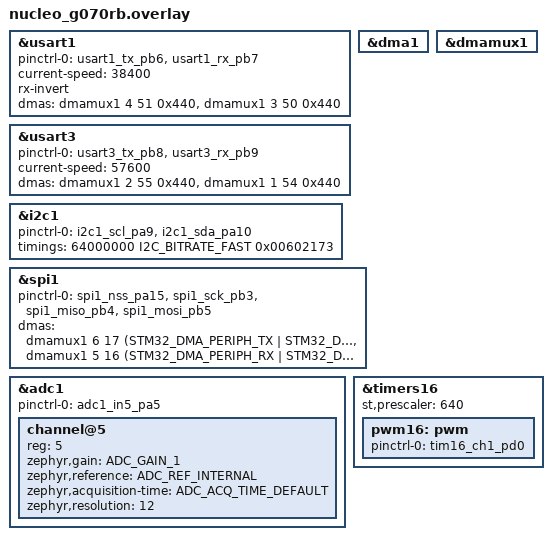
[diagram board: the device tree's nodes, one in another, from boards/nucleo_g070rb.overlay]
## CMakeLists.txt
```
# SPDX-License-Identifier: Apache-2.0

cmake_minimum_required(VERSION 3.20.0)
find_package(Zephyr REQUIRED HINTS $ENV{ZEPHYR_BASE})
project(lapan_imubk)

target_sources(app PRIVATE
	src/main.cpp
	src/sen_mti3.cpp
	src/sen_adxl.cpp
	src/sen_lsm6.cpp
	src/sen_lis3.cpp
	src/sen_ms56.cpp
	src/com_uart.cpp
	src/protocol_mgr.cpp
	src/util.cpp
	src/minmea.c
	)
```

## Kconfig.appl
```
mainmenu "MTIG4"

source "Kconfig.zephyr"
config MYAPP_STM32
	default y
	bool
	select USE_STM32_HAL_I2C
```

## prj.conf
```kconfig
CONFIG_CPP=y
CONFIG_NEWLIB_LIBC=y

CONFIG_I2C=y
CONFIG_PWM=y
CONFIG_ADC=y
CONFIG_ADC_STM32=y
# CONFIG_I2C_CALLBACK=y
# CONFIG_UART=y
CONFIG_UART_ASYNC_API=y

CONFIG_SPI=y
CONFIG_RING_BUFFER=y
CONFIG_SPI_STM32_DMA=y
# CONFIG_SPI_STM32_INTERRUPT=y
CONFIG_SPI_ASYNC=y
CONFIG_LOG=y
CONFIG_LOG_BACKEND_RTT=y
# CONFIG_SHELL=y
# CONFIG_SHELL_BACKENDS=y
# CONFIG_SHELL_BACKEND_RTT=y    

CONFIG_SPEED_OPTIMIZATIONS=y


CONFIG_BOOT_BANNER=n
# CONFIG_STDOUT_CONSOLE=y
# CONFIG_UART_CONSOLE=n
# CONFIG_RTT_CONSOLE=y
# CONFIG_USE_SEGGER_RTT=y
# CONFIG_THREAD_NAME=y
# CONFIG_DEBUG=y
# CONFIG_THREAD_ANALYZER=y
# CONFIG_THREAD_ANALYZER_AUTO=y
# CONFIG_THREAD_ANALYZER_AUTO_INTERVAL=10
# CONFIG_THREAD_ANALYZER_USE_LOG=y
```

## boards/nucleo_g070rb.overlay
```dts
&usart1 {
	pinctrl-0 = <&usart1_tx_pb6 &usart1_rx_pb7>;
	pinctrl-names = "default";
	current-speed = <38400>;
	status = "okay";
	rx-invert;

	dmas = <&dmamux1 4 51 0x440>,
	       <&dmamux1 3 50 0x440>;
	dma-names = "tx", "rx";
};

// &usart2 {
// 	pinctrl-0 = <&usart2_tx_pa2 &usart2_rx_pa3>;
// 	pinctrl-names = "default";
// 	current-speed = <115200>;
// 	status = "okay";
// };

&usart3 {
	pinctrl-0 = <&usart3_tx_pb8 &usart3_rx_pb9>;
	pinctrl-names = "default";
	current-speed = <57600>;
	status = "okay";
	
	dmas = <&dmamux1 2 55 0x440>,
	       <&dmamux1 1 54 0x440>;
	dma-names = "tx", "rx";
};


// &usart4 {
// 	pinctrl-0 = <&usart4_tx_pa0 &usart4_rx_pa1>;
// 	pinctrl-names = "default";
// 	current-speed = <115200>;
// 	status = "okay";
// };

&dma1 {
	status = "okay";
};

&dmamux1 {	
	status = "okay";
};

&i2c1 {
	pinctrl-0 = <&i2c1_scl_pa9 &i2c1_sda_pa10>;
    timings = <64000000 I2C_BITRATE_FAST 0x00602173>;
};

&spi1 {
	pinctrl-0 = <&spi1_nss_pa15 &spi1_sck_pb3 &spi1_miso_pb4 &spi1_mosi_pb5>;
	status = "okay";
	dmas = <&dmamux1 6 17 (STM32_DMA_PERIPH_TX | STM32_DMA_PRIORITY_HIGH)>,
		   <&dmamux1 5 16 (STM32_DMA_PERIPH_RX | STM32_DMA_PRIORITY_HIGH)>;
	dma-names = "tx", "rx";
};

&adc1 {
	#address-cells = <1>;
	#size-cells = <0>;

	pinctrl-0 = <&adc1_in5_pa5 >;
	pinctrl-names = "default";
	status = "okay";

	channel@5 {
		reg = <5>;
		zephyr,gain = "ADC_GAIN_1";
		zephyr,reference = "ADC_REF_INTERNAL";
		zephyr,acquisition-time = <ADC_ACQ_TIME_DEFAULT>;
		zephyr,resolution = <12>;
	};
};

&timers16 {
	st,prescaler = <640>;
	status = "okay";

	pwm16: pwm {
		status = "okay";
		pinctrl-0 = <&tim16_ch1_pd0>;
		pinctrl-names = "default";
	};
};
```

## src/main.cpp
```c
#include <stdint.h>
#include <stdio.h>
#include <stdlib.h>
#include <string.h>
#include <zephyr/kernel.h>
#include <zephyr/device.h>
#include <zephyr/drivers/gpio.h>
#include <zephyr/drivers/uart.h>
#include <zephyr/drivers/pwm.h>
#include <zephyr/drivers/adc.h>
#include <zephyr/sys/ring_buffer.h>

#include "sen_mti3.hpp"
#include "sen_adxl.hpp"
#include "sen_lsm6.hpp"
#include "sen_lis3.hpp"
#include "sen_ms56.hpp"
#include "com_uart.hpp"
#include "protocol_mgr.hpp"
#include "util.hpp"
#include "data.hpp"
#include "minmea.h"

#define STACKSIZE 1024
#define SMALLSTACKSIZE	512

#define ADXL_ADDR 0x53
#define LSM6_ADDR 0x6A
#define LIS3_ADDR 0x1E
#define MS56_ADDR 0x77

#ifndef ARCH_STACK_PTR_ALIGN
#define ARCH_STACK_PTR_ALIGN 8
#endif

static const struct device *const gpib		= DEVICE_DT_GET(DT_NODELABEL(gpiob));
static const struct device *const gpic		= DEVICE_DT_GET(DT_NODELABEL(gpioc));
static const struct device *const gpid		= DEVICE_DT_GET(DT_NODELABEL(gpiod));
static const struct device *const adcc1		= DEVICE_DT_GET(DT_NODELABEL(adc1));
static const struct device *const pwm_bz	= DEVICE_DT_GET(DT_NODELABEL(pwm16));
static const struct device *const spi_sen	= DEVICE_DT_GET(DT_NODELABEL(spi1));
static const struct device *const i2c_sen	= DEVICE_DT_GET(DT_NODELABEL(i2c2));
static const struct device *const uart_com	= DEVICE_DT_GET(DT_NODELABEL(usart3));
static const struct device *const uart_gps	= DEVICE_DT_GET(DT_NODELABEL(usart1));

static struct adc_channel_cfg adc1c5c = ADC_CHANNEL_CFG_DT(DT_CHILD(DT_NODELABEL(adc1), channel_5));

// Sensors are ring-buffered, except GPS and MS5611 since they works in round robin
RING_BUF_DECLARE(adxl_ring_buf, sizeof(ADXLRawData) * 2);
RING_BUF_DECLARE(lsm6_ring_buf, sizeof(LSM6RawData) * 2);
RING_BUF_DECLARE(lis3_ring_buf, sizeof(LIS3RawData) * 2);
RING_BUF_DECLARE(mti3_ring_buf, sizeof(MTI3RawData) * 2);
MS56RawData ms56_buf;
NMEARawData nmea_buf;

struct spi_config spi_sen_cfg = {
	.frequency = 1000000U,
	.operation = SPI_OP_MODE_MASTER | SPI_MODE_CPOL | SPI_MODE_CPHA | SPI_WORD_SET(8) | SPI_TRANSFER_MSB,
};

uint32_t i2c_sen_cfg = I2C_SPEED_SET(I2C_SPEED_FAST) | I2C_MODE_CONTROLLER;

uint16_t adcbuf;
struct adc_sequence adc_sen_seq = {
	.channels = 0b0000000000100000,
	.buffer = &adcbuf,
	.buffer_size = sizeof(adcbuf),
	.resolution = 12,
};

MTI3 *mti3 = new MTI3(spi_sen, spi_sen_cfg);
ADXL *adxl = new ADXL(i2c_sen, ADXL_ADDR);
LSM6 *lsm6 = new LSM6(i2c_sen, LSM6_ADDR);
LIS3 *lis3 = new LIS3(i2c_sen, LIS3_ADDR);
MS56 *ms56 = new MS56(i2c_sen, MS56_ADDR);

DATCOM *datcom = new DATCOM(uart_com);

// Should use semaphore instead of flags, but whatever
uint8_t sen_i2c_flag = 0;
uint8_t sen_spi_flag = 0;
uint8_t com_send_imu_flag = 0;
uint8_t com_send_gps_flag = 0;
uint8_t ctx_finish_flag = 0;
uint8_t buz_ping_flag = 0;
uint8_t uart_com_flag = 0;
uint8_t uart_gps_flag = 0;

uint8_t pktcounter = 0;
uint8_t rate_buz = 1;
uint8_t uart_com_buf[32];
uint8_t uart_gps_buf[128];

uart_event_rx com_uart_evt;
uart_event_rx gps_uart_evt;

///////////////////////////////////////////////////////////////////////////////
//	PREDECLARATIONS
///////////////////////////////////////////////////////////////////////////////

void sen_poll_exp(struct k_timer *timer);
void gps_poll_exp(struct k_timer *timer);
void dat_ping_exp(struct k_timer *timer);

K_TIMER_DEFINE(timer_sen, sen_poll_exp, NULL);
K_TIMER_DEFINE(timer_gps, gps_poll_exp, NULL);
K_TIMER_DEFINE(timer_buz, dat_ping_exp, NULL);

void buzzer_ping(int16_t freq)
{
	int8_t ret = 0;
	if (freq > 0)
	{
		ret = pwm_set_cycles(pwm_bz, 1, 100000 / freq, 50000 / freq, PWM_POLARITY_NORMAL);
	}
	else
	{
		ret = pwm_set_cycles(pwm_bz, 1, 10, 0, PWM_POLARITY_NORMAL);
	}
}

///////////////////////////////////////////////////////////////////////////////
//	SERIAL INTERRUPT CALLBACK
///////////////////////////////////////////////////////////////////////////////

void com_uart_cb(const struct device *dev, struct uart_event *evt, void *user_data)
{
	switch (evt->type)
	{
	case UART_TX_DONE:
		ctx_finish_flag = 1;
		break;
	case UART_TX_ABORTED:
		// should do something here really...
		break;
	case UART_RX_RDY:
		com_uart_evt = evt->data.rx;
		uart_com_flag = 1;
		break;
	default:
		break;
	}
}

void gps_uart_cb(const struct device *dev, struct uart_event *evt, void *user_data)
{
	switch (evt->type)
	{
	case UART_RX_RDY:
		gps_uart_evt = evt->data.rx;
		uart_gps_flag = 1;
		break;
	default:
		break;
	}
}

///////////////////////////////////////////////////////////////////////////////
//	DATA ACQUISITION
///////////////////////////////////////////////////////////////////////////////

void adxl_get_data()
{
	uint8_t cnt = 2;
	uint8_t adxldata[sizeof(ADXLRawData) * cnt];
	adxl->getMeasurement(adxldata, &cnt);
	for (int8_t i = 0; i < cnt; i++)
	{
		ring_buf_put(&adxl_ring_buf, &adxldata[i * sizeof(ADXLRawData)], sizeof(ADXLRawData));
	}
}

void lsm6_get_data()
{
	uint8_t cnt = 1;
	uint8_t lsm6data[sizeof(LSM6RawData)];
	lsm6->getMeasurement(lsm6data, &cnt);
	for (int8_t i = 0; i < cnt; i++)
	{
		ring_buf_put(&lsm6_ring_buf, &lsm6data[i * sizeof(LSM6RawData)], sizeof(LSM6RawData));
	}
}

void lis3_get_data()
{
	uint8_t cnt = 2;
	uint8_t lis3data[6];
	lis3->getMeasurement(lis3data, &cnt);

	for (int8_t i = 0; i < cnt; i++)
	{
		ring_buf_put(&lis3_ring_buf, &lis3data[i * sizeof(LIS3RawData)], sizeof(LIS3RawData));
	}
}

void ms56_get_data()
{
	uint8_t cnt = 1;
	ms56->getMeasurement((uint8_t *)&ms56_buf, &cnt);
}

uint32_t mti3_parse_32b(uint8_t *data)
{
	return data[0] << 24 | data[1] << 16 | data[2] << 8 | data[3];
}

int8_t mti3_parse_measdata(uint8_t *measData, uint8_t len, MTI3RawData *data)
{
	if (len < 2)
	{
		return -1;
	}

	if (measData[0] != XSENS_MTDATA2)
	{
		return -2;
	}

	if (len - 3 != measData[1])
	{
		return -3;
	}

	uint8_t idx = 2;

	while (idx < (len - 3))
	{
		uint16_t dataID = ((uint16_t)measData[idx + 1] | ((uint16_t)measData[idx] << 8));
		uint8_t dataLen = measData[idx + 2];

		switch (dataID & 0xFFFF0)
		{
		case XDI_ACCELERATION:
			data->accX = mti3_parse_32b(&measData[idx + 3]);
			data->accY = mti3_parse_32b(&measData[idx + 7]);
			data->accZ = mti3_parse_32b(&measData[idx + 11]);
			break;
		case XDI_RATEOFTURN:
			data->rotX = mti3_parse_32b(&measData[idx + 3]);
			data->rotY = mti3_parse_32b(&measData[idx + 7]);
			data->rotZ = mti3_parse_32b(&measData[idx + 11]);
			break;
		case XDI_MAGNETICFIELD:
			data->magX = mti3_parse_32b(&measData[idx + 3]);
			data->magY = mti3_parse_32b(&measData[idx + 7]);
			data->magZ = mti3_parse_32b(&measData[idx + 11]);
			break;
		case XDI_EULERANGLES:
			data->roll = mti3_parse_32b(&measData[idx + 3]);
			data->pitch = mti3_parse_32b(&measData[idx + 7]);
			data->yaw = mti3_parse_32b(&measData[idx + 11]);
			break;
		case XDI_DELTAV:
			data->dvX = mti3_parse_32b(&measData[idx + 3]);
			data->dvY = mti3_parse_32b(&measData[idx + 7]);
			data->dvZ = mti3_parse_32b(&measData[idx + 11]);
			break;
		case XDI_DELTAQ:
			data->dqA = mti3_parse_32b(&measData[idx + 3]);
			data->dqB = mti3_parse_32b(&measData[idx + 7]);
			data->dqC = mti3_parse_32b(&measData[idx + 11]);
			data->dqD = mti3_parse_32b(&measData[idx + 15]);
			break;
		case XDI_SAMPLETIMEFINE:
			data->sTime = mti3_parse_32b(&measData[idx + 3]);
			break;
		case XDI_PACKETCOUNTER:
			data->counter = mti3_parse_32b(&measData[idx + 3]);
			break;
		case XDI_TEMPERATURE:
			ms56_buf.temp2 = ((mti3_parse_32b(&measData[idx + 3]) >> 8) * 100) >> 12;
			break;
		default:
			break;
		}
		idx += dataLen + 3;
	}
	return 0;
}

void mti3_get_data()
{
	uint16_t notifCnt;
	uint16_t measCnt;

	mti3->getStatus(&notifCnt, &measCnt);
	if (measCnt)
	{
		uint8_t measData[measCnt + 4];
		mti3->getMeasurement(measData, measCnt);
		MTI3RawData data;
		mti3_parse_measdata(&measData[4], measCnt, &data);
		ring_buf_put(&mti3_ring_buf, (uint8_t *)&data, sizeof(MTI3RawData));
	}

	mti3->getStatus(&notifCnt, &measCnt);
	if (measCnt)
	{
		uint8_t measData[measCnt + 4];
		mti3->getMeasurement(measData, measCnt);
		MTI3RawData data;
		mti3_parse_measdata(&measData[4], measCnt, &data);
		ring_buf_put(&mti3_ring_buf, (uint8_t *)&data, sizeof(MTI3RawData));
	}
	if (notifCnt)
	{
		uint8_t notifData[notifCnt + 4];
		mti3->getNotification(notifData, notifCnt);
	}
}

int8_t mti3_get_msg()
{
	uint16_t notifCnt;
	uint16_t measCnt;

	mti3->getStatus(&notifCnt, &measCnt);
	if (notifCnt)
	{
		uint8_t notifData[notifCnt + 4];
		mti3->getNotification(notifData, notifCnt);
	}
	return notifCnt;
}

void mti3_setup()
{
	uint8_t goMeas[] = {XSENS_GOTOMEASUREMENT, 0};
	mti3->setConfig(goMeas, 2);
}

///////////////////////////////////////////////////////////////////////////////
//	DATCOM PACKET HANDLER
///////////////////////////////////////////////////////////////////////////////

void com_send_imu()
{
	ADXLRawData adxldata = {0};
	LSM6RawData lsm6data = {0};
	LIS3RawData lis3data = {0};
	MTI3RawData mti3data = {0};
	ring_buf_get(&adxl_ring_buf, (uint8_t *)&adxldata, sizeof(ADXLRawData));
	ring_buf_get(&lsm6_ring_buf, (uint8_t *)&lsm6data, sizeof(LSM6RawData));
	ring_buf_get(&lis3_ring_buf, (uint8_t *)&lis3data, sizeof(LIS3RawData));
	ring_buf_get(&mti3_ring_buf, (uint8_t *)&mti3data, sizeof(MTI3RawData));

	uint8_t *data = new uint8_t[52]();

	PROTOCOL_IMU pld_imu{data, 1, pktcounter++};
	pld_imu.putADXLData(&adxldata);
	pld_imu.putLSM6Data(&lsm6data);
	pld_imu.putLIS3Data(&lis3data);
	pld_imu.putMTI3Data(&mti3data);
	pld_imu.finish();

	datcom_payload *pp = new datcom_payload{
		.len = 52,
		.pld = data,
	};

	datcom->putPayload(pp);
}

void com_send_gps()
{
	uint8_t *data = new uint8_t[24]();

	PROTOCOL_GPS pld_gps{data, 2, pktcounter++};
	pld_gps.putNMEAData(&nmea_buf);
	pld_gps.putMS56Data(&ms56_buf);
	pld_gps.finish();

	datcom_payload *pp = new datcom_payload{
		.len = 24,
		.pld = data,
	};

	datcom->putPayload(pp);
}

///////////////////////////////////////////////////////////////////////////////
//	EVENT GENERATORS
///////////////////////////////////////////////////////////////////////////////

void sen_poll_exp(struct k_timer *timer)
{
	sen_i2c_flag = 1;
	sen_spi_flag = 1;
	com_send_imu_flag = 1;
}

void gps_poll_exp(struct k_timer *timer)
{
	com_send_gps_flag = 1;
}

void dat_ping_exp(struct k_timer *timer)
{
	buz_ping_flag = 1;
}

///////////////////////////////////////////////////////////////////////////////
//	THREAD LOOPS
///////////////////////////////////////////////////////////////////////////////

void loop_sen_i2c()
{
	while (1)
	{
		if (sen_i2c_flag)
		{
			sen_i2c_flag = 0;
			adxl_get_data();
			lsm6_get_data();
			lis3_get_data();
			ms56_get_data();
		}

		k_usleep(10);
	}
}

void loop_sen_spi()
{
	while (1)
	{
		if (sen_spi_flag)
		{
			sen_spi_flag = 0;
			mti3_get_data();
		}

		k_usleep(10);
	}
}

void loop_gps()
{
	while (1)
	{
		if (uart_gps_flag)
		{
			uart_gps_flag = 0;
			uart_rx_disable(uart_gps);
			switch (minmea_sentence_id((char *)gps_uart_evt.buf, false))
			{
			case MINMEA_SENTENCE_GGA:
				struct minmea_sentence_gga f_gga;
				if (minmea_parse_gga(&f_gga, (char *)gps_uart_evt.buf))
				{
					nmea_buf.lat = (f_gga.latitude.value / (f_gga.latitude.scale * 100)) * 6000000 + (f_gga.latitude.value % (f_gga.latitude.scale * 100) * (100000 / f_gga.latitude.scale));
					nmea_buf.lon = (f_gga.longitude.value / (f_gga.longitude.scale * 100)) * 6000000 + (f_gga.longitude.value % (f_gga.longitude.scale * 100) * (100000 / f_gga.latitude.scale));
					nmea_buf.alt = f_gga.altitude.value / f_gga.altitude.scale;
					nmea_buf.tim = f_gga.time.seconds + f_gga.time.minutes * 60 + f_gga.time.hours * 3600;
				}
				break;
			case MINMEA_SENTENCE_VTG:
				struct minmea_sentence_vtg f_vtg;
				if (minmea_parse_vtg(&f_vtg, (char *)gps_uart_evt.buf))
				{
					nmea_buf.vel = f_vtg.speed_kph.value * 2 / f_vtg.speed_kph.scale;
					nmea_buf.hdg = f_vtg.true_track_degrees.value * 64 / f_vtg.true_track_degrees.scale;
				}
				break;
			default:
				break;
			}
			memset(uart_gps_buf, 0, sizeof(uart_gps_buf));
			uart_rx_enable(uart_gps, uart_gps_buf, 128, 1000);
		}

		k_usleep(10);
	}
}

void loop_com_imu()
{
	while (1)
	{
		if (uart_com_flag)
		{
			uart_com_flag = 0;
			uart_rx_disable(uart_com);

			if (strcmp((char *)com_uart_evt.buf, "SHUTDOWN") == 0)
			{
				k_timer_stop(&timer_buz);
				k_timer_stop(&timer_sen);
				k_timer_stop(&timer_gps);

				buzzer_ping(2500);
				k_sleep(K_MSEC(200));
				buzzer_ping(1500);
				k_sleep(K_MSEC(200));
				buzzer_ping(750);

				gpio_pin_configure(gpib, 14, GPIO_OUTPUT_INACTIVE);
			}

			memset(uart_com_buf, 0, sizeof(uart_com_buf));
			uart_rx_enable(uart_com, uart_com_buf, 32, 1000);
		}

		if (com_send_imu_flag)
		{
			com_send_imu_flag = 0;
			com_send_imu();
		}

		if (ctx_finish_flag)
		{
			ctx_finish_flag = 0;
			datcom->txFinish();
		}

		k_usleep(10);
	}
}

void loop_com_gps()
{
	while (1)
	{
		if (com_send_gps_flag)
		{
			com_send_gps_flag = 0;
			com_send_gps();
		}

		k_usleep(10);
	}
}

void loop_buz()
{
	while (1)
	{
		if (buz_ping_flag)
		{

			buz_ping_flag = 0;
			buzzer_ping(7500);
			k_msleep(100);
			buzzer_ping(0);
			adc_read(adcc1, &adc_sen_seq);

			if (adcbuf < 2400)
			{
				rate_buz = 1;
			}
			else if (rate_buz != 10)
			{
				rate_buz = 10;
			}

			k_timer_start(&timer_buz, K_SECONDS(rate_buz), K_SECONDS(rate_buz));
		}
		else
		{
			k_usleep(10);
		}
	}
}

K_THREAD_DEFINE(thread_sen_spi,	STACKSIZE,		loop_sen_spi,	NULL, NULL, NULL, 1,	0, 0);
K_THREAD_DEFINE(thread_sen_i2c,	STACKSIZE,		loop_sen_i2c,	NULL, NULL, NULL, 2,	0, 0);
K_THREAD_DEFINE(thread_gps,		STACKSIZE,		loop_gps,		NULL, NULL, NULL, 3,	0, 0);
K_THREAD_DEFINE(thread_com_imu,	STACKSIZE,		loop_com_imu,	NULL, NULL, NULL, 4,	0, 0);
K_THREAD_DEFINE(thread_com_gps,	STACKSIZE,		loop_com_gps,	NULL, NULL, NULL, 5,	0, 0);
K_THREAD_DEFINE(thread_buz,		SMALLSTACKSIZE,	loop_buz,		NULL, NULL, NULL, 99,	0, 0);

int main()
{
	gpio_pin_configure(gpic, 6,		GPIO_OUTPUT_INACTIVE); // LED
	gpio_pin_configure(gpic, 7,		GPIO_OUTPUT_INACTIVE); // LED
	gpio_pin_configure(gpid, 2,		GPIO_OUTPUT_INACTIVE);
	gpio_pin_configure(gpib, 14,	GPIO_INPUT);
	gpio_pin_configure(gpid, 3,		GPIO_OUTPUT_INACTIVE);

	i2c_configure(i2c_sen, i2c_sen_cfg);

	uart_callback_set(uart_com, com_uart_cb, NULL);
	uart_callback_set(uart_gps, gps_uart_cb, NULL);

	adc_channel_setup(adcc1, &adc1c5c);

	mti3_setup();
	adxl->setup();
	lsm6->setup();
	lis3->setup();
	ms56->setup();

	uart_rx_enable(uart_com, uart_com_buf, 32, 1000);
	uart_rx_enable(uart_gps, uart_gps_buf, 128, 1000);

	buzzer_ping(1000);
	k_sleep(K_MSEC(200));
	buzzer_ping(2000);
	k_sleep(K_MSEC(200));
	buzzer_ping(4000);
	k_sleep(K_MSEC(200));
	buzzer_ping(0);

	k_timer_start(&timer_sen, K_MSEC(500),			K_MSEC(10));					 // 100Hz = 10mS
	k_timer_start(&timer_gps, K_MSEC(503),			K_MSEC(100));				 // 20Hz = 50mS
	k_timer_start(&timer_buz, K_SECONDS(rate_buz),	K_SECONDS(rate_buz)); // 20Hz = 50mS

	uint8_t maincnt = 0;
	while (1)
	{
		if (maincnt++ % 8 == 0)
		{
			gpio_pin_set(gpic, 6, 1);
		}
		else
		{
			gpio_pin_set(gpic, 6, 0);
		}

		k_sleep(K_MSEC(100));
	}
}
```

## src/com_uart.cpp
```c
#include "com_uart.hpp"

DATCOM::DATCOM(struct device const *uart)
{
	_uart = uart;
}

DATCOM::~DATCOM()
{
}

int8_t DATCOM::setup()
{
	return 0;
}

int8_t DATCOM::putPayload(datcom_payload *data)
{
	if ((_pldHead + 1) % COM_RINGBUFFER_LEN == _pldTail)
	{
		return -1;
	}

	_pld[_pldHead] = data;
	_pldHead = (_pldHead + 1) % COM_RINGBUFFER_LEN;

	if (!_uartTxBusy)
	{
		this->send();
	}
	return 0;
}

int8_t DATCOM::send()
{
	if (_pldTail == _pldHead)
	{
		return -1;
	}
	_uartTxBusy = 1;
	return uart_tx(_uart, _pld[_pldTail]->pld, _pld[_pldTail]->len, SYS_FOREVER_US);
}

int8_t DATCOM::txFinish()
{
	// buffer deletion SHOULD BE incorporated in class destructor
	delete _pld[_pldTail]->pld;
	delete _pld[_pldTail];

	_pldTail = (_pldTail + 1) % COM_RINGBUFFER_LEN;

	_uartTxBusy = 0;
	if (_pldTail != _pldHead)
	{
		this->send();
	}
	return 0;
}
```

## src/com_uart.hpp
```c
#ifndef DATCOM_HPP
#define DATCOM_HPP

#include <zephyr/kernel.h>
#include <zephyr/device.h>
#include <zephyr/drivers/uart.h>
#include <zephyr/sys/ring_buffer.h>
#include "util.hpp"

#define COM_RINGBUFFER_LEN 8

typedef struct datcom_payload
{
	uint8_t len;
	uint8_t *pld;
} datcom_payload;

class DATCOM
{
public:
	DATCOM(struct device const *uart);
	~DATCOM();

	int8_t setup();

	int8_t putPayload(datcom_payload *pld);
	int8_t txFinish();
	int8_t txAbort();
private:
	int8_t send();

	struct device const *_uart;
	datcom_payload *_pld[COM_RINGBUFFER_LEN];
	uint8_t _uartTxBusy = 0;
	uint8_t _pldHead = 0;
	uint8_t _pldTail = 0;
};

#endif
```

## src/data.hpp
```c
#ifndef DATA_HPP
#define DATA_HPP

#include <stdint.h>

typedef struct MTI3RawData
{
	int32_t pitch;
	int32_t roll;
	int32_t yaw;
	int32_t accX;
	int32_t accY;
	int32_t accZ;
	int32_t rotX;
	int32_t rotY;
	int32_t rotZ;
	int32_t magX;
	int32_t magY;
	int32_t magZ;
	int32_t dvX;
	int32_t dvY;
	int32_t dvZ;
	int32_t dqA;
	int32_t dqB;
	int32_t dqC;
	int32_t dqD;
	uint32_t sTime;
	uint32_t counter;
} MTI3RawData;

typedef struct ADXLRawData
{
	int16_t accX;
	int16_t accY;
	int16_t accZ;
} ADXLRawData;

typedef struct LSM6RawData
{
	int16_t rotX;
	int16_t rotY;
	int16_t rotZ;
	int16_t accX;
	int16_t accY;
	int16_t accZ;
} LSM6RAWData;

typedef struct LIS3RawData
{
	int16_t magX;
	int16_t magY;
	int16_t magZ;
} LIS3RAWData;

typedef struct MS56RawData
{
	uint16_t pres;
	int16_t temp1;
	int16_t temp2;
} MS56RawData;

typedef struct NMEARawData
{
	int32_t lat;
	int32_t lon;
	uint16_t alt;
	uint16_t vel;
	uint16_t hdg;
	uint16_t tim;
} NMEARawData;

#endif
```

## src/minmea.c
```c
/*
 * Copyright © 2014 Kosma Moczek <kosma@cloudyourcar.com>
 * This program is free software. It comes without any warranty, to the extent
 * permitted by applicable law. You can redistribute it and/or modify it under
 * the terms of the Do What The Fuck You Want To Public License, Version 2, as
 * published by Sam Hocevar. See the COPYING file for more details.
 */

#include "minmea.h"

#include <stdlib.h>
#include <string.h>
#include <stdarg.h>

#define boolstr(s) ((s) ? "true" : "false")

static int hex2int(char c)
{
	if (c >= '0' && c <= '9')
		return c - '0';
	if (c >= 'A' && c <= 'F')
		return c - 'A' + 10;
	if (c >= 'a' && c <= 'f')
		return c - 'a' + 10;
	return -1;
}

uint8_t minmea_checksum(const char *sentence)
{
	// Support senteces with or without the starting dollar sign.
	if (*sentence == '$')
		sentence++;

	uint8_t checksum = 0x00;

	// The optional checksum is an XOR of all bytes between "$" and "*".
	while (*sentence && *sentence != '*')
		checksum ^= *sentence++;

	return checksum;
}

bool minmea_check(const char *sentence, bool strict)
{
	uint8_t checksum = 0x00;

	// A valid sentence starts with "$".
	if (*sentence++ != '$')
		return false;

	// The optional checksum is an XOR of all bytes between "$" and "*".
	while (*sentence && *sentence != '*' && isprint((unsigned char) *sentence))
		checksum ^= *sentence++;

	// If checksum is present...
	if (*sentence == '*') {
		// Extract checksum.
		sentence++;
		int upper = hex2int(*sentence++);
		if (upper == -1)
			return false;
		int lower = hex2int(*sentence++);
		if (lower == -1)
			return false;
		int expected = upper << 4 | lower;

		// Check for checksum mismatch.
		if (checksum != expected)
			return false;
	} else if (strict) {
		// Discard non-checksummed frames in strict mode.
		return false;
	}

	// The only stuff allowed at this point is a newline.
	while (*sentence == '\r' || *sentence == '\n') {
		sentence++;
	}
	
	if (*sentence) {
		return false;
	}

	return true;
}

bool minmea_scan(const char *sentence, const char *format, ...)
{
	bool result = false;
	bool optional = false;

	if (sentence == NULL)
		return false;

	va_list ap;
	va_start(ap, format);

	const char *field = sentence;
#define next_field() \
	do { \
		/* Progress to the next field. */ \
		while (minmea_isfield(*sentence)) \
			sentence++; \
		/* Make sure there is a field there. */ \
		if (*sentence == ',') { \
			sentence++; \
			field = sentence; \
		} else { \
			field = NULL; \
		} \
	} while (0)

	while (*format) {
		char type = *format++;

		if (type == ';') {
			// All further fields are optional.
			optional = true;
			continue;
		}

		if (!field && !optional) {
			// Field requested but we ran out if input. Bail out.
			goto parse_error;
		}

		switch (type) {
			case 'c': { // Single character field (char).
				char value = '\0';

				if (field && minmea_isfield(*field))
					value = *field;

				*va_arg(ap, char *) = value;
			} break;

			case 'd': { // Single character direction field (int).
				int value = 0;

				if (field && minmea_isfield(*field)) {
					switch (*field) {
						case 'N':
						case 'E':
							value = 1;
							break;
						case 'S':
						case 'W':
							value = -1;
							break;
						default:
							goto parse_error;
					}
				}

				*va_arg(ap, int *) = value;
			} break;

			case 'f': { // Fractional value with scale (struct minmea_float).
				int sign = 0;
				int_least32_t value = -1;
				int_least32_t scale = 0;

				if (field) {
					while (minmea_isfield(*field)) {
						if (*field == '+' && !sign && value == -1) {
							sign = 1;
						} else if (*field == '-' && !sign && value == -1) {
							sign = -1;
						} else if (isdigit((unsigned char) *field)) {
							int digit = *field - '0';
							if (value == -1)
								value = 0;
							if (value > (INT_LEAST32_MAX-digit) / 10) {
								/* we ran out of bits, what do we do? */
								if (scale) {
									/* truncate extra precision */
									break;
								} else {
									/* integer overflow. bail out. */
									goto parse_error;
								}
							}
							value = (10 * value) + digit;
							if (scale)
								scale *= 10;
						} else if (*field == '.' && scale == 0) {
							scale = 1;
						} else if (*field == ' ') {
							/* Allow spaces at the start of the field. Not NMEA
							 * conformant, but some modules do this. */
							if (sign != 0 || value != -1 || scale != 0)
								goto parse_error;
						} else {
							goto parse_error;
						}
						field++;
					}
				}

				if ((sign || scale) && value == -1)
					goto parse_error;

				if (value == -1) {
					/* No digits were scanned. */
					value = 0;
					scale = 0;
				} else if (scale == 0) {
					/* No decimal point. */
					scale = 1;
				}
				if (sign)
					value *= sign;

				*va_arg(ap, struct minmea_float *) = (struct minmea_float) {value, scale};
			} break;

			case 'i': { // Integer value, default 0 (int).
				int value = 0;

				if (field) {
					char *endptr;
					value = strtol(field, &endptr, 10);
					if (minmea_isfield(*endptr))
						goto parse_error;
				}

				*va_arg(ap, int *) = value;
			} break;

			case 's': { // String value (char *).
				char *buf = va_arg(ap, char *);

				if (field) {
					while (minmea_isfield(*field))
						*buf++ = *field++;
				}

				*buf = '\0';
			} break;

			case 't': { // NMEA talker+sentence identifier (char *).
				// This field is always mandatory.
				if (!field)
					goto parse_error;

				if (field[0] != '$')
					goto parse_error;
				for (int f=0; f<5; f++)
					if (!minmea_isfield(field[1+f]))
						goto parse_error;

				char *buf = va_arg(ap, char *);
				memcpy(buf, field+1, 5);
				buf[5] = '\0';
			} break;

			case 'D': { // Date (int, int, int), -1 if empty.
				struct minmea_date *date = va_arg(ap, struct minmea_date *);

				int d = -1, m = -1, y = -1;

				if (field && minmea_isfield(*field)) {
					// Always six digits.
					for (int f=0; f<6; f++)
						if (!isdigit((unsigned char) field[f]))
							goto parse_error;

					char dArr[] = {field[0], field[1], '\0'};
					char mArr[] = {field[2], field[3], '\0'};
					char yArr[] = {field[4], field[5], '\0'};
					d = strtol(dArr, NULL, 10);
					m = strtol(mArr, NULL, 10);
					y = strtol(yArr, NULL, 10);
				}

				date->day = d;
				date->month = m;
				date->year = y;
			} break;

			case 'T': { // Time (int, int, int, int), -1 if empty.
				struct minmea_time *time_ = va_arg(ap, struct minmea_time *);

				int h = -1, i = -1, s = -1, u = -1;

				if (field && minmea_isfield(*field)) {
					// Minimum required: integer time.
					for (int f=0; f<6; f++)
						if (!isdigit((unsigned char) field[f]))
							goto parse_error;

					char hArr[] = {field[0], field[1], '\0'};
					char iArr[] = {field[2], field[3], '\0'};
					char sArr[] = {field[4], field[5], '\0'};
					h = strtol(hArr, NULL, 10);
					i = strtol(iArr, NULL, 10);
					s = strtol(sArr, NULL, 10);
					field += 6;

					// Extra: fractional time. Saved as microseconds.
					if (*field++ == '.') {
						uint32_t value = 0;
						uint32_t scale = 1000000LU;
						while (isdigit((unsigned char) *field) && scale > 1) {
							value = (value * 10) + (*field++ - '0');
							scale /= 10;
						}
						u = value * scale;
					} else {
						u = 0;
					}
				}

				time_->hours = h;
				time_->minutes = i;
				time_->seconds = s;
				time_->microseconds = u;
			} break;

			case '_': { // Ignore the field.
			} break;

			default: { // Unknown.
				goto parse_error;
			}
		}

		next_field();
	}

	result = true;

parse_error:
	va_end(ap);
	return result;
}

bool minmea_talker_id(char talker[3], const char *sentence)
{
	char type[6];
	if (!minmea_scan(sentence, "t", type))
		return false;

	talker[0] = type[0];
	talker[1] = type[1];
	talker[2] = '\0';

	return true;
}

enum minmea_sentence_id minmea_sentence_id(const char *sentence, bool strict)
{
	if (!minmea_check(sentence, strict))
		return MINMEA_INVALID;

	char type[6];
	if (!minmea_scan(sentence, "t", type))
		return MINMEA_INVALID;

	if (!strcmp(type+2, "GBS"))
		return MINMEA_SENTENCE_GBS;
	if (!strcmp(type+2, "GGA"))
		return MINMEA_SENTENCE_GGA;
	if (!strcmp(type+2, "GLL"))
		return MINMEA_SENTENCE_GLL;
	if (!strcmp(type+2, "GSA"))
		return MINMEA_SENTENCE_GSA;
	if (!strcmp(type+2, "GST"))
		return MINMEA_SENTENCE_GST;
	if (!strcmp(type+2, "GSV"))
		return MINMEA_SENTENCE_GSV;
	if (!strcmp(type+2, "RMC"))
		return MINMEA_SENTENCE_RMC;
	if (!strcmp(type+2, "VTG"))
		return MINMEA_SENTENCE_VTG;
	if (!strcmp(type+2, "ZDA"))
		return MINMEA_SENTENCE_ZDA;

	return MINMEA_UNKNOWN;
}

bool minmea_parse_gbs(struct minmea_sentence_gbs *frame, const char *sentence)
{
	// $GNGBS,170556.00,3.0,2.9,8.3,,,,*5C
	char type[6];
	if (!minmea_scan(sentence, "tTfffifff",
			type,
			&frame->time,
			&frame->err_latitude,
			&frame->err_longitude,
			&frame->err_altitude,
			&frame->svid,
			&frame->prob,
			&frame->bias,
			&frame->stddev
			))
		return false;
	if (strcmp(type+2, "GBS"))
		return false;

	return true;
}

bool minmea_parse_rmc(struct minmea_sentence_rmc *frame, const char *sentence)
{
	// $GPRMC,081836,A,3751.65,S,14507.36,E,000.0,360.0,130998,011.3,E*62
	char type[6];
	char validity;
	int latitude_direction;
	int longitude_direction;
	int variation_direction;
	if (!minmea_scan(sentence, "tTcfdfdffDfd",
			type,
			&frame->time,
			&validity,
			&frame->latitude, &latitude_direction,
			&frame->longitude, &longitude_direction,
			&frame->speed,
			&frame->course,
			&frame->date,
			&frame->variation, &variation_direction))
		return false;
	if (strcmp(type+2, "RMC"))
		return false;

	frame->valid = (validity == 'A');
	frame->latitude.value *= latitude_direction;
	frame->longitude.value *= longitude_direction;
	frame->variation.value *= variation_direction;

	return true;
}

bool minmea_parse_gga(struct minmea_sentence_gga *frame, const char *sentence)
{
	// $GPGGA,123519,4807.038,N,01131.000,E,1,08,0.9,545.4,M,46.9,M,,*47
	char type[6];
	int latitude_direction;
	int longitude_direction;

	if (!minmea_scan(sentence, "tTfdfdiiffcfcf_",
			type,
			&frame->time,
			&frame->latitude, &latitude_direction,
			&frame->longitude, &longitude_direction,
			&frame->fix_quality,
			&frame->satellites_tracked,
			&frame->hdop,
			&frame->altitude, &frame->altitude_units,
			&frame->height, &frame->height_units,
			&frame->dgps_age))
		return false;
	if (strcmp(type+2, "GGA"))
		return false;

	frame->latitude.value *= latitude_direction;
	frame->longitude.value *= longitude_direction;

	return true;
}

bool minmea_parse_gsa(struct minmea_sentence_gsa *frame, const char *sentence)
{
	// $GPGSA,A,3,04,05,,09,12,,,24,,,,,2.5,1.3,2.1*39
	char type[6];

	if (!minmea_scan(sentence, "tciiiiiiiiiiiiifff",
			type,
			&frame->mode,
			&frame->fix_type,
			&frame->sats[0],
			&frame->sats[1],
			&frame->sats[2],
			&frame->sats[3],
			&frame->sats[4],
			&frame->sats[5],
			&frame->sats[6],
			&frame->sats[7],
			&frame->sats[8],
			&frame->sats[9],
			&frame->sats[10],
			&frame->sats[11],
			&frame->pdop,
			&frame->hdop,
			&frame->vdop))
		return false;
	if (strcmp(type+2, "GSA"))
		return false;

	return true;
}

bool minmea_parse_gll(struct minmea_sentence_gll *frame, const char *sentence)
{
	// $GPGLL,3723.2475,N,12158.3416,W,161229.487,A,A*41$;
	char type[6];
	int latitude_direction;
	int longitude_direction;

	if (!minmea_scan(sentence, "tfdfdTc;c",
			type,
			&frame->latitude, &latitude_direction,
			&frame->longitude, &longitude_direction,
			&frame->time,
			&frame->status,
			&frame->mode))
		return false;
	if (strcmp(type+2, "GLL"))
		return false;

	frame->latitude.value *= latitude_direction;
	frame->longitude.value *= longitude_direction;

	return true;
}

bool minmea_parse_gst(struct minmea_sentence_gst *frame, const char *sentence)
{
	// $GPGST,024603.00,3.2,6.6,4.7,47.3,5.8,5.6,22.0*58
	char type[6];

	if (!minmea_scan(sentence, "tTfffffff",
			type,
			&frame->time,
			&frame->rms_deviation,
			&frame->semi_major_deviation,
			&frame->semi_minor_deviation,
			&frame->semi_major_orientation,
			&frame->latitude_error_deviation,
			&frame->longitude_error_deviation,
			&frame->altitude_error_deviation))
		return false;
	if (strcmp(type+2, "GST"))
		return false;

	return true;
}

bool minmea_parse_gsv(struct minmea_sentence_gsv *frame, const char *sentence)
{
	// $GPGSV,3,1,11,03,03,111,00,04,15,270,00,06,01,010,00,13,06,292,00*74
	// $GPGSV,3,3,11,22,42,067,42,24,14,311,43,27,05,244,00,,,,*4D
	// $GPGSV,4,2,11,08,51,203,30,09,45,215,28*75
	// $GPGSV,4,4,13,39,31,170,27*40
	// $GPGSV,4,4,13*7B
	char type[6];

	if (!minmea_scan(sentence, "tiii;iiiiiiiiiiiiiiii",
			type,
			&frame->total_msgs,
			&frame->msg_nr,
			&frame->total_sats,
			&frame->sats[0].nr,
			&frame->sats[0].elevation,
			&frame->sats[0].azimuth,
			&frame->sats[0].snr,
			&frame->sats[1].nr,
			&frame->sats[1].elevation,
			&frame->sats[1].azimuth,
			&frame->sats[1].snr,
			&frame->sats[2].nr,
			&frame->sats[2].elevation,
			&frame->sats[2].azimuth,
			&frame->sats[2].snr,
			&frame->sats[3].nr,
			&frame->sats[3].elevation,
			&frame->sats[3].azimuth,
			&frame->sats[3].snr
			)) {
		return false;
	}
	if (strcmp(type+2, "GSV"))
		return false;

	return true;
}

bool minmea_parse_vtg(struct minmea_sentence_vtg *frame, const char *sentence)
{
	// $GPVTG,054.7,T,034.4,M,005.5,N,010.2,K*48
	// $GPVTG,156.1,T,140.9,M,0.0,N,0.0,K*41
	// $GPVTG,096.5,T,083.5,M,0.0,N,0.0,K,D*22
	// $GPVTG,188.36,T,,M,0.820,N,1.519,K,A*3F
	char type[6];
	char c_true, c_magnetic, c_knots, c_kph, c_faa_mode;

	if (!minmea_scan(sentence, "t;fcfcfcfcc",
			type,
			&frame->true_track_degrees,
			&c_true,
			&frame->magnetic_track_degrees,
			&c_magnetic,
			&frame->speed_knots,
			&c_knots,
			&frame->speed_kph,
			&c_kph,
			&c_faa_mode))
		return false;
	if (strcmp(type+2, "VTG"))
		return false;
	// values are only valid with the accompanying characters
	if (c_true != 'T')
		frame->true_track_degrees.scale = 0;
	if (c_magnetic != 'M')
		frame->magnetic_track_degrees.scale = 0;
	if (c_knots != 'N')
		frame->speed_knots.scale = 0;
	if (c_kph != 'K')
		frame->speed_kph.scale = 0;
	frame->faa_mode = (enum minmea_faa_mode)c_faa_mode;

	return true;
}

bool minmea_parse_zda(struct minmea_sentence_zda *frame, const char *sentence)
{
  // $GPZDA,201530.00,04,07,2002,00,00*60
  char type[6];

  if(!minmea_scan(sentence, "tTiiiii",
		  type,
		  &frame->time,
		  &frame->date.day,
		  &frame->date.month,
		  &frame->date.year,
		  &frame->hour_offset,
		  &frame->minute_offset))
	  return false;
  if (strcmp(type+2, "ZDA"))
	  return false;

  // check offsets
  if (abs(frame->hour_offset) > 13 ||
	  frame->minute_offset > 59 ||
	  frame->minute_offset < 0)
	  return false;

  return true;
}

int minmea_getdatetime(struct tm *tm, const struct minmea_date *date, const struct minmea_time *time_)
{
	if (date->year == -1 || time_->hours == -1)
		return -1;

	memset(tm, 0, sizeof(*tm));
	if (date->year < 80) {
		tm->tm_year = 2000 + date->year - 1900; // 2000-2079
	} else if (date->year >= 1900) {
		tm->tm_year = date->year - 1900;        // 4 digit year, use directly
	} else {
		tm->tm_year = date->year;               // 1980-1999
	}
	tm->tm_mon = date->month - 1;
	tm->tm_mday = date->day;
	tm->tm_hour = time_->hours;
	tm->tm_min = time_->minutes;
	tm->tm_sec = time_->seconds;

	return 0;
}

int minmea_gettime(struct timespec *ts, const struct minmea_date *date, const struct minmea_time *time_)
{
	struct tm tm;
	if (minmea_getdatetime(&tm, date, time_))
		return -1;

	time_t timestamp = timegm(&tm); /* See README.md if your system lacks timegm(). */
	if (timestamp != (time_t)-1) {
		ts->tv_sec = timestamp;
		ts->tv_nsec = time_->microseconds * 1000;
		return 0;
	} else {
		return -1;
	}
}

/* vim: set ts=4 sw=4 et: */
```

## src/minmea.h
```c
/*
 * Copyright © 2014 Kosma Moczek <kosma@cloudyourcar.com>
 * This program is free software. It comes without any warranty, to the extent
 * permitted by applicable law. You can redistribute it and/or modify it under
 * the terms of the Do What The Fuck You Want To Public License, Version 2, as
 * published by Sam Hocevar. See the COPYING file for more details.
 */

#ifndef MINMEA_H
#define MINMEA_H

#ifdef __cplusplus
extern "C" {
#endif

#include <ctype.h>
#include <stdint.h>
#include <stdbool.h>
#include <time.h>
#include <math.h>
#ifdef MINMEA_INCLUDE_COMPAT
#include <minmea_compat.h>
#endif

#ifndef MINMEA_MAX_SENTENCE_LENGTH
#define MINMEA_MAX_SENTENCE_LENGTH 80
#endif

enum minmea_sentence_id {
	MINMEA_INVALID = -1,
	MINMEA_UNKNOWN = 0,
	MINMEA_SENTENCE_GBS,
	MINMEA_SENTENCE_GGA,
	MINMEA_SENTENCE_GLL,
	MINMEA_SENTENCE_GSA,
	MINMEA_SENTENCE_GST,
	MINMEA_SENTENCE_GSV,
	MINMEA_SENTENCE_RMC,
	MINMEA_SENTENCE_VTG,
	MINMEA_SENTENCE_ZDA,
};

struct minmea_float {
	int_least32_t value;
	int_least32_t scale;
};

struct minmea_date {
	int day;
	int month;
	int year;
};

struct minmea_time {
	int hours;
	int minutes;
	int seconds;
	int microseconds;
};

struct minmea_sentence_gbs {
	struct minmea_time time;
	struct minmea_float err_latitude;
	struct minmea_float err_longitude;
	struct minmea_float err_altitude;
	int svid;
	struct minmea_float prob;
	struct minmea_float bias;
	struct minmea_float stddev;
};

struct minmea_sentence_rmc {
	struct minmea_time time;
	bool valid;
	struct minmea_float latitude;
	struct minmea_float longitude;
	struct minmea_float speed;
	struct minmea_float course;
	struct minmea_date date;
	struct minmea_float variation;
};

struct minmea_sentence_gga {
	struct minmea_time time;
	struct minmea_float latitude;
	struct minmea_float longitude;
	int fix_quality;
	int satellites_tracked;
	struct minmea_float hdop;
	struct minmea_float altitude; char altitude_units;
	struct minmea_float height; char height_units;
	struct minmea_float dgps_age;
};

enum minmea_gll_status {
	MINMEA_GLL_STATUS_DATA_VALID = 'A',
	MINMEA_GLL_STATUS_DATA_NOT_VALID = 'V',
};

// FAA mode added to some fields in NMEA 2.3.
enum minmea_faa_mode {
	MINMEA_FAA_MODE_AUTONOMOUS = 'A',
	MINMEA_FAA_MODE_DIFFERENTIAL = 'D',
	MINMEA_FAA_MODE_ESTIMATED = 'E',
	MINMEA_FAA_MODE_MANUAL = 'M',
	MINMEA_FAA_MODE_SIMULATED = 'S',
	MINMEA_FAA_MODE_NOT_VALID = 'N',
	MINMEA_FAA_MODE_PRECISE = 'P',
};

struct minmea_sentence_gll {
	struct minmea_float latitude;
	struct minmea_float longitude;
	struct minmea_time time;
	char status;
	char mode;
};

struct minmea_sentence_gst {
	struct minmea_time time;
	struct minmea_float rms_deviation;
	struct minmea_float semi_major_deviation;
	struct minmea_float semi_minor_deviation;
	struct minmea_float semi_major_orientation;
	struct minmea_float latitude_error_deviation;
	struct minmea_float longitude_error_deviation;
	struct minmea_float altitude_error_deviation;
};

enum minmea_gsa_mode {
	MINMEA_GPGSA_MODE_AUTO = 'A',
	MINMEA_GPGSA_MODE_FORCED = 'M',
};

enum minmea_gsa_fix_type {
	MINMEA_GPGSA_FIX_NONE = 1,
	MINMEA_GPGSA_FIX_2D = 2,
	MINMEA_GPGSA_FIX_3D = 3,
};

struct minmea_sentence_gsa {
	char mode;
	int fix_type;
	int sats[12];
	struct minmea_float pdop;
	struct minmea_float hdop;
	struct minmea_float vdop;
};

struct minmea_sat_info {
	int nr;
	int elevation;
	int azimuth;
	int snr;
};

struct minmea_sentence_gsv {
	int total_msgs;
	int msg_nr;
	int total_sats;
	struct minmea_sat_info sats[4];
};

struct minmea_sentence_vtg {
	struct minmea_float true_track_degrees;
	struct minmea_float magnetic_track_degrees;
	struct minmea_float speed_knots;
	struct minmea_float speed_kph;
	enum minmea_faa_mode faa_mode;
};

struct minmea_sentence_zda {
	struct minmea_time time;
	struct minmea_date date;
	int hour_offset;
	int minute_offset;
};

/**
 * Calculate raw sentence checksum. Does not check sentence integrity.
 */
uint8_t minmea_checksum(const char *sentence);

/**
 * Check sentence validity and checksum. Returns true for valid sentences.
 */
bool minmea_check(const char *sentence, bool strict);

/**
 * Determine talker identifier.
 */
bool minmea_talker_id(char talker[3], const char *sentence);

/**
 * Determine sentence identifier.
 */
enum minmea_sentence_id minmea_sentence_id(const char *sentence, bool strict);

/**
 * Scanf-like processor for NMEA sentences. Supports the following formats:
 * c - single character (char *)
 * d - direction, returned as 1/-1, default 0 (int *)
 * f - fractional, returned as value + scale (struct minmea_float *)
 * i - decimal, default zero (int *)
 * s - string (char *)
 * t - talker identifier and type (char *)
 * D - date (struct minmea_date *)
 * T - time stamp (struct minmea_time *)
 * _ - ignore this field
 * ; - following fields are optional
 * Returns true on success. See library source code for details.
 */
bool minmea_scan(const char *sentence, const char *format, ...);

/*
 * Parse a specific type of sentence. Return true on success.
 */
bool minmea_parse_gbs(struct minmea_sentence_gbs *frame, const char *sentence);
bool minmea_parse_rmc(struct minmea_sentence_rmc *frame, const char *sentence);
bool minmea_parse_gga(struct minmea_sentence_gga *frame, const char *sentence);
bool minmea_parse_gsa(struct minmea_sentence_gsa *frame, const char *sentence);
bool minmea_parse_gll(struct minmea_sentence_gll *frame, const char *sentence);
bool minmea_parse_gst(struct minmea_sentence_gst *frame, const char *sentence);
bool minmea_parse_gsv(struct minmea_sentence_gsv *frame, const char *sentence);
bool minmea_parse_vtg(struct minmea_sentence_vtg *frame, const char *sentence);
bool minmea_parse_zda(struct minmea_sentence_zda *frame, const char *sentence);

/**
 * Convert GPS UTC date/time representation to a UNIX calendar time.
 */
int minmea_getdatetime(struct tm *tm, const struct minmea_date *date, const struct minmea_time *time_);

/**
 * Convert GPS UTC date/time representation to a UNIX timestamp.
 */
int minmea_gettime(struct timespec *ts, const struct minmea_date *date, const struct minmea_time *time_);

/**
 * Rescale a fixed-point value to a different scale. Rounds towards zero.
 */
static inline int_least32_t minmea_rescale(const struct minmea_float *f, int_least32_t new_scale)
{
	if (f->scale == 0)
		return 0;
	if (f->scale == new_scale)
		return f->value;
	if (f->scale > new_scale)
		return (f->value + ((f->value > 0) - (f->value < 0)) * f->scale/new_scale/2) / (f->scale/new_scale);
	else
		return f->value * (new_scale/f->scale);
}

/**
 * Convert a fixed-point value to a floating-point value.
 * Returns NaN for "unknown" values.
 */
static inline float minmea_tofloat(const struct minmea_float *f)
{
	if (f->scale == 0)
		return NAN;
	return (float) f->value / (float) f->scale;
}

/**
 * Convert a raw coordinate to a floating point DD.DDD... value.
 * Returns NaN for "unknown" values.
 */
static inline float minmea_tocoord(const struct minmea_float *f)
{
	if (f->scale == 0)
		return NAN;
	if (f->scale  > (INT_LEAST32_MAX / 100))
		return NAN;
	if (f->scale < (INT_LEAST32_MIN / 100))
		return NAN;
	int_least32_t degrees = f->value / (f->scale * 100);
	int_least32_t minutes = f->value % (f->scale * 100);
	return (float) degrees + (float) minutes / (60 * f->scale);
}

/**
 * Check whether a character belongs to the set of characters allowed in a
 * sentence data field.
 */
static inline bool minmea_isfield(char c) {
	return isprint((unsigned char) c) && c != ',' && c != '*';
}

#ifdef __cplusplus
}
#endif

#endif /* MINMEA_H */

/* vim: set ts=4 sw=4 et: */
```

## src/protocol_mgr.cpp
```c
#include "protocol_mgr.hpp"

PROTOCOL::PROTOCOL(uint8_t *data, uint8_t id, uint8_t count, uint8_t pldlen)
{
	_data = data;
	_id = id;
	_pldlen = pldlen;
	_count = count;

	memset(_data, 0, _pldlen + 4);	// why is this even necessary?

	_data[0] = 0xA5;
	_data[1] = _id << 6 | (_pldlen & 0x3F);
	_data[2] = _count;
}

PROTOCOL::~PROTOCOL()
{
}

int8_t PROTOCOL::finish()
{
	return calcCRC();
}

uint8_t PROTOCOL::head(uint16_t data)
{
	return data & 0xFF;
}

uint8_t PROTOCOL::half(uint16_t data1, uint16_t data2)
{
	return (data2 & 0x0F) << 4 | (data1 >> 8 & 0x0F);
}

uint8_t PROTOCOL::tail(uint16_t data)
{
	return data >> 4 & 0xFF;
}

int8_t PROTOCOL::calcCRC()
{
	// supposed to be CRC-8-CCITT
	_data[3 + _pldlen] = crc8(&_data[1], _pldlen + 2, 0x07, 0x00, false);
	return 0;
}

PROTOCOL_IMU::PROTOCOL_IMU(uint8_t *data, uint8_t id, uint8_t count) : PROTOCOL(data, id, count, 48)
{
}

PROTOCOL_IMU::~PROTOCOL_IMU()
{
}

int8_t PROTOCOL_IMU::putADXLData(ADXLRawData *data)
{
	_data[3] = head(data->accX);			 // XX  1234 -> 23
	_data[4] = half(data->accX, data->accY); // XY  1234 -> 40 | 1234 -> 02
	_data[5] = tail(data->accY);			 // YY  1234 -> 34
	_data[6] = head(data->accZ);			 // ZZ
	_data[7] = half(data->accZ, 0);			 // Z0

	return 0;
}

int8_t PROTOCOL_IMU::putLSM6Data(LSM6RawData *data)
{
	_data[7] = _data[7] | half(0, data->accX >> 4);		// 0X
	_data[8] = tail(data->accX >> 4);					// XX
	_data[9] = head(data->accY >> 4);					// YY
	_data[10] = half(data->accY >> 4, data->accZ >> 4); // YZ
	_data[11] = tail(data->accZ >> 4);					// ZZ

	_data[12] = head(data->rotX >> 4);					// XX
	_data[13] = half(data->rotX >> 4, data->rotY >> 4); // XY
	_data[14] = tail(data->rotY >> 4);					// YY
	_data[15] = head(data->rotZ >> 4);					// ZZ
	_data[16] = half(data->rotZ >> 4, 0);				// Z0
	return 0;
}

int8_t PROTOCOL_IMU::putLIS3Data(LIS3RawData *data)
{
	_data[16] = _data[16] | half(0, data->magX >> 4);	// 0X
	_data[17] = tail(data->magX >> 4);					// XX
	_data[18] = head(data->magY >> 4);					// YY
	_data[19] = half(data->magY >> 4, data->magZ >> 4); // YZ
	_data[20] = tail(data->magZ >> 4);					// ZZ
	return 0;
}

int8_t PROTOCOL_IMU::putMTI3Data(MTI3RawData *data)
{
	_data[21] = head(data->accX >> 17);					   // XX    Accelerometer in ms^(-2)  max +/- 256    MTI default is 12.20
	_data[22] = half(data->accX >> 17, data->accY >> 17);  // XY
	_data[23] = tail(data->accY >> 17);					   // YY
	_data[24] = head(data->accZ >> 17);					   // ZZ
	_data[25] = half(data->accZ >> 17, data->rotX >> 11);  // ZX    Gyro in rad/s
	_data[26] = tail(data->rotX >> 11);					   // XX
	_data[27] = head(data->rotY >> 11);					   // YY
	_data[28] = half(data->rotY >> 11, data->rotZ >> 11);  // YZ
	_data[29] = tail(data->rotZ >> 11);					   // ZZ
	_data[30] = head(data->magX >> 11);					   // XX
	_data[31] = half(data->magX >> 11, data->magY >> 11);  // XY
	_data[32] = tail(data->magY >> 11);					   // YY
	_data[33] = head(data->magZ >> 11);					   // ZZ
	_data[34] = half(data->magZ >> 11, data->pitch >> 17); // ZX
	_data[35] = tail(data->pitch >> 17);				   // XX
	_data[36] = head(data->roll >> 17);					   // YY
	_data[37] = half(data->roll >> 17, data->yaw >> 17);   // YZ
	_data[38] = tail(data->yaw >> 17);					   // ZZ
	_data[39] = head(data->dvX >> 16);					   // XX
	_data[40] = half(data->dvX >> 16, data->dvY >> 16);	   // XY
	_data[41] = tail(data->dvY >> 16);					   // YY
	_data[42] = head(data->dvZ >> 16);					   // ZZ
	_data[43] = half(data->dvZ >> 16, data->dqA >> 16);	   // ZX
	_data[44] = tail(data->dqA >> 16);					   // XX
	_data[45] = head(data->dqB >> 16);					   // YY
	_data[46] = half(data->dqB >> 16, data->dqC >> 16);	   // YZ
	_data[47] = tail(data->dqC >> 16);					   // ZZ
	_data[48] = head(data->dqD >> 16);					   // ZZ
	_data[49] = half(data->dqD >> 16, data->sTime >> 0);   // ZZ
	_data[50] = tail(data->sTime >> 0);					   // ZZ

	return 0;
}

PROTOCOL_GPS::PROTOCOL_GPS(uint8_t *data, uint8_t id, uint8_t count) : PROTOCOL(data, id, count, 20)
{
}

PROTOCOL_GPS::~PROTOCOL_GPS()
{
}

int8_t PROTOCOL_GPS::putNMEAData(NMEARawData *data)
{
	uint32_t lat = data->lat + 54000000;  // offset from -9
	uint32_t lon = data->lon + 654000000; // offset from -109
	_data[3] = lat & 0xFF;
	_data[4] = lat >> 8 & 0xFF;
	_data[5] = lat >> 16 & 0xFF;
	_data[6] = lon & 0xFF;
	_data[7] = lon >> 8 & 0xFF;
	_data[8] = lon >> 16 & 0xFF;
	_data[9] = data->alt & 0xFF;
	_data[10] = data->alt >> 8 & 0xFF;
	_data[11] = data->vel & 0xFF;
	_data[12] = data->vel >> 8 & 0xFF;
	_data[13] = data->hdg & 0xFF;
	_data[14] = data->hdg >> 8 & 0xFF;
	_data[15] = data->tim & 0xFF;
	_data[16] = data->tim >> 8 & 0xFF;

	return 0;
}

int8_t PROTOCOL_GPS::putMS56Data(MS56RawData *data)
{
	_data[17] = data->pres & 0xFF;
	_data[18] = data->pres >> 8 & 0xFF;
	_data[19] = data->temp1 & 0xFF;
	_data[20] = data->temp1 >> 8 & 0xFF;
	_data[21] = data->temp2 & 0xFF;
	_data[22] = data->temp2 >> 8 & 0xFF;

	return 0;
}
```

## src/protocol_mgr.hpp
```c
#ifndef PROTOCOL_HPP
#define PROTOCOL_HPP

#include "util.hpp"
#include "data.hpp"
#include <zephyr/sys/crc.h>

class PROTOCOL
{
public:
	PROTOCOL(uint8_t *data, uint8_t id, uint8_t count, uint8_t pldlen);
	~PROTOCOL();

	int8_t finish();

private:
	int8_t calcCRC();

protected:
	uint8_t head(uint16_t data);
	uint8_t half(uint16_t data1, uint16_t data2);
	uint8_t tail(uint16_t data);

	uint8_t *_data;
	uint8_t _id;
	uint8_t _pldlen;
	uint8_t _count;
};

class PROTOCOL_IMU : public PROTOCOL
{
public:
	PROTOCOL_IMU(uint8_t *data, uint8_t id, uint8_t count);
	~PROTOCOL_IMU();

	int8_t putADXLData(ADXLRawData *data);
	int8_t putLSM6Data(LSM6RawData *data);
	int8_t putLIS3Data(LIS3RawData *data);
	int8_t putMTI3Data(MTI3RawData *data);
};

class PROTOCOL_GPS : public PROTOCOL
{
public:
	PROTOCOL_GPS(uint8_t *data, uint8_t id, uint8_t count);
	~PROTOCOL_GPS();

	int8_t putNMEAData(NMEARawData *data);
	int8_t putMS56Data(MS56RawData *data);
};

#endif
```

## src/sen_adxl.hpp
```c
#ifndef SEN_ADXL_HPP
#define SEN_ADXL_HPP

#include <zephyr/kernel.h>
#include <zephyr/device.h>
#include <zephyr/drivers/i2c.h>
#include "util.hpp"

class ADXL
{
public:
	ADXL(struct device const *i2c, uint8_t addr);
	~ADXL();

	int8_t setup();
	int8_t getMeasurement(uint8_t *data, uint8_t *cnt);

private:
	struct device const *_i2c;
	const uint8_t _addr;
};

#endif
```
